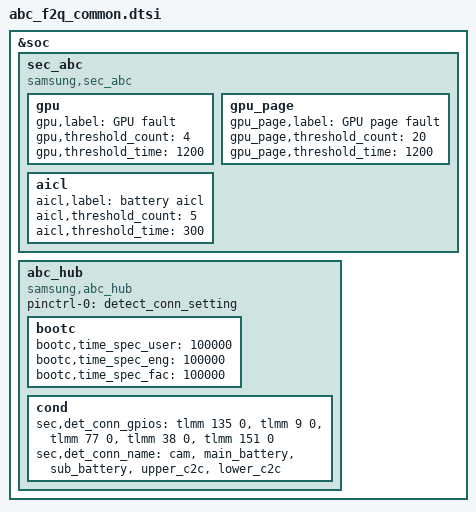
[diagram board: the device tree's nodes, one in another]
/* Copyright (c) 2019, The Linux Foundation. All rights reserved.
 *
 * This program is free software; you can redistribute it and/or modify
 * it under the terms of the GNU General Public License version 2 and
 * only version 2 as published by the Free Software Foundation.
 *
 * This program is distributed in the hope that it will be useful,
 * but WITHOUT ANY WARRANTY; without even the implied warranty of
 * MERCHANTABILITY or FITNESS FOR A PARTICULAR PURPOSE.  See the
 * GNU General Public License for more details.
 */

&soc {
	sec_abc {
		compatible = "samsung,sec_abc";
		status = "okay";

		gpu {
			gpu,label="GPU fault";
			gpu,threshold_count=<4>;
			gpu,threshold_time=<1200>;
		};
		gpu_page {
			gpu_page,label="GPU page fault";
			gpu_page,threshold_count=<20>;
			gpu_page,threshold_time=<1200>;
		};
		aicl {
			aicl,label="battery aicl";
			aicl,threshold_count=<5>;
			aicl,threshold_time=<300>;
		};
	};

	abc_hub {
		compatible = "samsung,abc_hub";
		status = "okay";

		pinctrl-names = "det_ap_connect";
		pinctrl-0 = <&detect_conn_setting>;

		bootc {
			bootc,time_spec_user = <100000>; /* user binary user build */
			bootc,time_spec_eng = <100000>; /* user binary eng build */
			bootc,time_spec_fac = <100000>; /* factory binary */
		};

		cond {
			sec,det_conn_gpios = <&tlmm 135 0 /* CAM_DETECT */
						&tlmm 9 0 /* MAIN_BAT_DETECT */
						&tlmm 77 0 /* SUB_BAT_DETECT */
						&tlmm 38 0 /* UPPER_C2C_DETECT */
						&tlmm 151 0>; /* LOWER_C2C_DETECT */
			sec,det_conn_name = "cam", "main_battery", "sub_battery", "upper_c2c", "lower_c2c";
		};
	};
};
